# bcm2835_lpa register map
Vendor: BROADCOM; Series: BCM2835; File version: A
CPU: CA72 r0p0, little endian, MPU, FPU, 2 interrupt priority bits
Registers are 32-bit, read-write, reset 0x0 unless marked. A register's access mark holds for its fields unless they carry their own. Offsets are from the block's base; [hi:lo] are bit positions; {n}, {i} and the like mark numbered series.

## PWM0 — Broadcom PWM
Base 0x2020C000
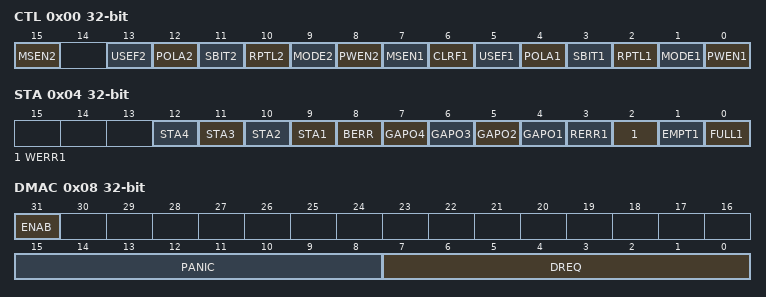
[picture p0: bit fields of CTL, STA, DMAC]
0x00 CTL — Control
  [15] MSEN2 — M/S mode for channel 2
  [13] USEF2 — Use FIFO for channel 2
  [12] POLA2 — Channel 2 polarity inverted
  [11] SBIT2 — State when not transmitting on channel 2
  [10] RPTL2 — Repeat last value from FIFO for channel 2
  [9] MODE2 — Channel 2 mode
    0=PWM; 1=SERIAL
  [8] PWEN2 — Enable channel 2
  [7] MSEN1 — M/S mode for channel 1
  [6] CLRF1 — Clear FIFO
  [5] USEF1 — Use FIFO for channel 1
  [4] POLA1 — Channel 1 polarity inverted
  [3] SBIT1 — State when not transmitting on channel 1
  [2] RPTL1 — Repeat last value from FIFO for channel 1
  [1] MODE1 — Channel 1 mode
    0=PWM; 1=SERIAL
  [0] PWEN1 — Enable channel 1
0x04 STA — Status
  [n+8] STA{n} (n=1..4) — Channel {n} state
  [8] BERR — Bus error
  [n+3] GAPO{n} (n=1..4) — Channel {n} gap occurred
  [3] RERR1 — FIFO read error
  [2] WERR1 — FIFO write error
  [1] EMPT1 — FIFO empty
  [0] FULL1 — FIFO full
0x08 DMAC — DMA control
  [31] ENAB — DMA enabled
  [15:8] PANIC — DMA threshold for panic signal
  [7:0] DREQ — DMA threshold for DREQ signal
0x10 RNG1 reset 0x20 — Range for channel 1
0x14 DAT1 — Channel 1 data
0x18 FIF1 wo — FIFO input
0x20 RNG2 reset 0x20 — Range for channel 2
0x24 DAT2 — Channel 2 data

## AUX — Three auxiliary peripherals
Base 0x20215000
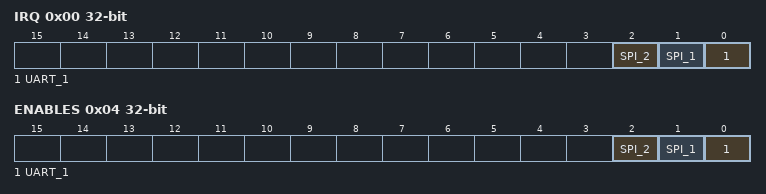
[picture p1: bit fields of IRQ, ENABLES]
0x00 IRQ — Interrupt status
  [2] SPI_2 — SPI2 interrupt active
  [1] SPI_1 — SPI1 interrupt active
  [0] UART_1 — UART1 interrupt active
0x04 ENABLES — Enable sub-peripherals
  [2] SPI_2 — SPI2 enabled
  [1] SPI_1 — SPI1 enabled
  [0] UART_1 — UART1 enabled

## UART1 — Mini UART
Base 0x20215040
0x00 IO — I/O Data
  [7:0] DATA — FIFO access
0x00 BAUDL 8-bit (alternate view of IO) — Lower bits of baudrate when DLAB is set
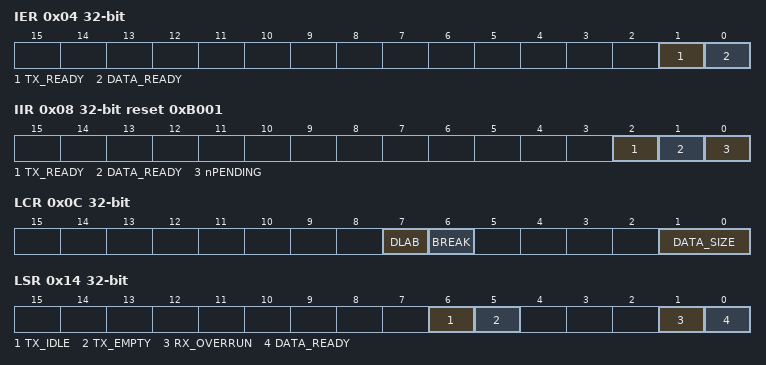
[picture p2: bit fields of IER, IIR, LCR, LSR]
0x04 IER — Interrupt Enable
  [1] TX_READY — Transmit FIFO is empty
  [0] DATA_READY — Receive FIFO has at least 1 byte
0x04 BAUDH 8-bit (alternate view of IER) — High bits of baudrate when DLAB is set
0x08 IIR reset 0xB001 — Interrupt Identify
  [2] TX_READY — Transmit FIFO is empty
  [1] DATA_READY — Receive FIFO has at least 1 byte
  [0] nPENDING — No pending interrupt
0x0C LCR — Line control
  [7] DLAB — First two registers are baudrate
  [6] BREAK — Pull TX low continuously to send break
  [1:0] DATA_SIZE — UART word size
    0=7BIT; 3=8BIT
0x10 MCR — Modem Control
  [1] RTS — RTS is low
0x14 LSR — Line Status
  [6] TX_IDLE — Transmit FIFO empty and all bits shifted out
  [5] TX_EMPTY — Transmit FIFO has room for at least one byte
  [1] RX_OVERRUN — Receive FIFO overrun
  [0] DATA_READY — Receive FIFO has at least one byte
0x18 MSR — Modem Status
  [4] CTS — CTS is low
0x1C SCRATCH 8-bit
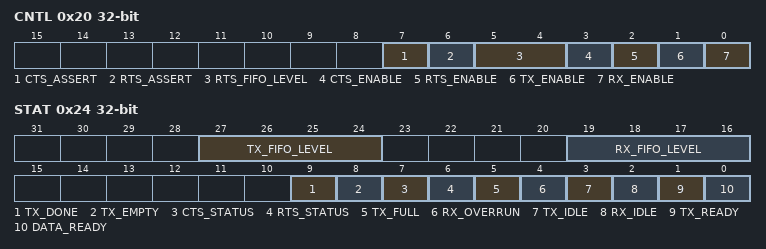
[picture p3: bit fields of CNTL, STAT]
0x20 CNTL — Control
  [7] CTS_ASSERT — CTS assert level
    0=HIGH (Assert high); 1=LOW (Assert low)
  [6] RTS_ASSERT — RTS assert level
    0=HIGH (Assert high); 1=LOW (Assert low)
  [5:4] RTS_FIFO_LEVEL — FIFO level to de-assert RTS
    0=3EMPTY (3 empty spaces); 1=2EMPTY (2 empty spaces); 2=1EMPTY (1 empty spaces); 3=4EMPTY (4 empty spaces)
  [3] CTS_ENABLE — Enable auto transmit flow control with CTS
  [2] RTS_ENABLE — Enable auto receive flow control with RTS
  [1] TX_ENABLE — Enable transmit
  [0] RX_ENABLE — Enable receive
0x24 STAT — Status
  [27:24] TX_FIFO_LEVEL — How many entries are filled in the TX FIFO
  [19:16] RX_FIFO_LEVEL — How many entries are filled in the RX FIFO
  [9] TX_DONE — Transmit FIFO is empty and transmitter is idle
  [8] TX_EMPTY — Transmit FIFO is completely empty
  [7] CTS_STATUS — CTS state
  [6] RTS_STATUS — RTS state
  [5] TX_FULL — Transmit FIFO is full
  [4] RX_OVERRUN — Receive FIFO overrun
  [3] TX_IDLE — Transmitter is idle
  [2] RX_IDLE — Receiver is idle
  [1] TX_READY — Transmit FIFO has space for at least one symbol
  [0] DATA_READY — Receive FIFO has at least one symbol
0x28 BAUD 16-bit — Baudrate
